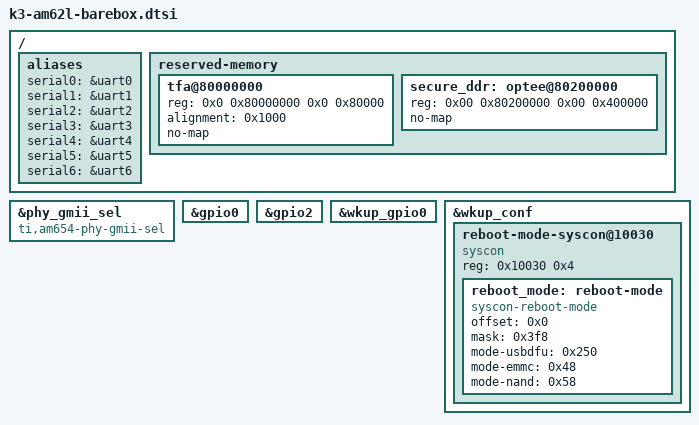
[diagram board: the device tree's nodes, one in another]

&phy_gmii_sel {
	compatible = "ti,am654-phy-gmii-sel", "syscon";
};

&gpio0 {
	status = "okay";
};

&gpio2 {
	status = "okay";
};

&wkup_gpio0 {
	status = "okay";
};

&wkup_conf {
	reboot-mode-syscon@10030 {
		compatible = "syscon", "simple-mfd";
		reg = <0x10030 0x4>;

		reboot_mode: reboot-mode {
			compatible = "syscon-reboot-mode";
			offset = <0x0>;
			mask = <0x3f8>;
			mode-usbdfu = <0x250>;
			mode-emmc = <0x48>;
			mode-nand = <0x58>;
		};
	};
};

/ {
	aliases {
		serial0 = &uart0;
		serial1 = &uart1;
		serial2 = &uart2;
		serial3 = &uart3;
		serial4 = &uart4;
		serial5 = &uart5;
		serial6 = &uart6;
	};

	reserved-memory {
		#address-cells = <2>;
		#size-cells = <2>;
		ranges;

		tfa@80000000 {
			reg = <0x0 0x80000000 0x0 0x80000>;
			alignment = <0x1000>;
			no-map;
		};

		secure_ddr: optee@80200000 {
			reg = <0x00 0x80200000 0x00 0x400000>;
			no-map;
		};
	};
};
